# ATSAMG55G19 device description
Architecture: CORTEX-M4; Family: SAMG; Series: SAMG55
Registers are 32-bit, read-write, no defined reset value unless marked. A register's access mark holds for its fields unless they carry their own. Offsets are from the block's base; [hi:lo] are bit positions.

## PDMIC — Pulse Density Modulation Interface Controller
Instances: PDMIC0 0x4002C000, PDMIC1 0x40030000
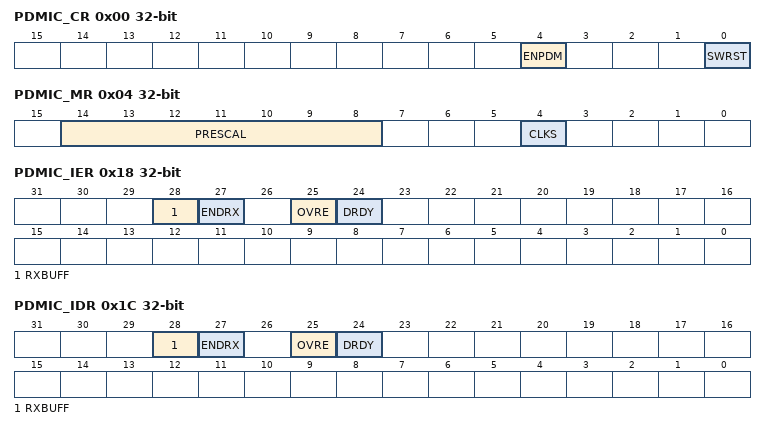
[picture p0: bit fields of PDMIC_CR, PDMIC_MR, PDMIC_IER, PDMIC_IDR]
0x00 PDMIC_CR — Control Register
  [4] ENPDM — Enable PDM
  [0] SWRST — Software Reset
0x04 PDMIC_MR — Mode Register
  [14:8] PRESCAL — Prescaler Rate Selection
  [4] CLKS — Clock Source Selection
0x14 PDMIC_CDR ro — Converted Data Register
  [31:0] DATA — Data Converted
0x18 PDMIC_IER wo (atomic set of PDMIC_IMR) — Interrupt Enable Register
  [28] RXBUFF — Receive Buffer Full Interrupt Enable
  [27] ENDRX — End of Receive Buffer Interrupt Enable
  [25] OVRE — Overrun Error Interrupt Enable
  [24] DRDY — Data Ready Interrupt Enable
0x1C PDMIC_IDR wo (atomic clear of PDMIC_IMR) — Interrupt Disable Register
  [28] RXBUFF — Receive Buffer Full Interrupt Disable
  [27] ENDRX — End of Receive Buffer Interrupt Disable
  [25] OVRE — General Overrun Error Interrupt Disable
  [24] DRDY — Data Ready Interrupt Disable
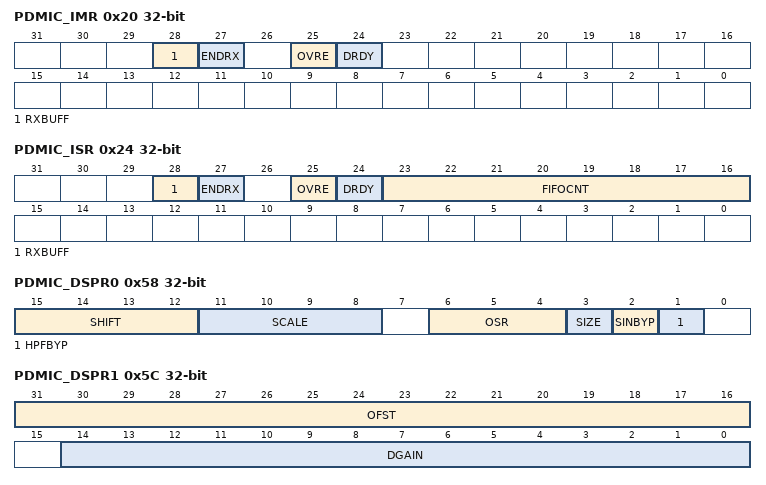
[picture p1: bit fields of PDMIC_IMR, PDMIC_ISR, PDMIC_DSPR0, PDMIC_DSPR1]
0x20 PDMIC_IMR ro (atomic read) — Interrupt Mask Register
  [28] RXBUFF — Receive Buffer Full Interrupt Mask
  [27] ENDRX — End of Receive Buffer Interrupt Mask
  [25] OVRE — General Overrun Error Interrupt Mask
  [24] DRDY — Data Ready Interrupt Mask
0x24 PDMIC_ISR ro (atomic read) — Interrupt Status Register
  [28] RXBUFF — RX Buffer Full
  [27] ENDRX — End of RX Buffer
  [25] OVRE — Overrun Error
  [24] DRDY — Data Ready
  [23:16] FIFOCNT — FIFO Count
0x58 PDMIC_DSPR0 — DSP Configuration Register 0
  [15:12] SHIFT — Data Shift
  [11:8] SCALE — Data Scale
  [6:4] OSR — Oversampling Ratio
    0=Oversampling ratio is 128; 1=Oversampling ratio is 64
  [3] SIZE — Data Size
  [2] SINBYP — SINCC Filter Bypass
  [1] HPFBYP — High-Pass Filter Bypass
0x5C PDMIC_DSPR1 — DSP Configuration Register 1
  [31:16] OFST — Offset Correction
  [14:0] DGAIN — Gain Correction
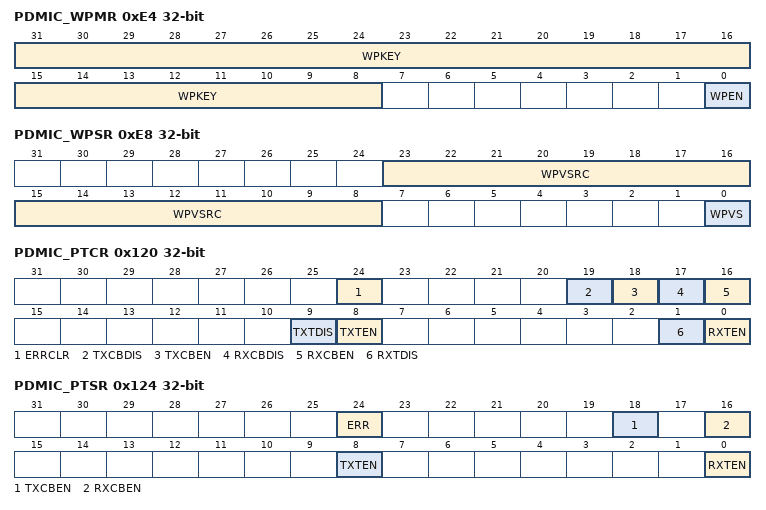
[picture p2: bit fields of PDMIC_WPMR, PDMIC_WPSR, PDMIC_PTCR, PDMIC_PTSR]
0xE4 PDMIC_WPMR — Write Protection Mode Register
  [31:8] WPKEY — Write Protect Key
    0x414443=PASSWD (Writing any other value in this field aborts the write operation of the WPEN bit.Always reads as 0.)
  [0] WPEN — Write Protection Enable
0xE8 PDMIC_WPSR ro — Write Protection Status Register
  [23:8] WPVSRC — Write Protection Violation Source
  [0] WPVS — Write Protection Violation Status
0x100 PDMIC_RPR — Receive Pointer Register
  [31:0] RXPTR
0x104 PDMIC_RCR — Receive Counter Register
  [15:0] RXCTR
0x110 PDMIC_RNPR — Receive Next Pointer Register
  [31:0] RXNPTR — Receive Next Pointer
0x114 PDMIC_RNCR — Receive Next Counter Register
  [15:0] RXNCTR — Receive Next Counter
0x120 PDMIC_PTCR wo — Transfer Control Register
  [24] ERRCLR — Transfer Bus Error Clear
  [19] TXCBDIS — Transmitter Circular Buffer Disable
  [18] TXCBEN — Transmitter Circular Buffer Enable
  [17] RXCBDIS — Receiver Circular Buffer Disable
  [16] RXCBEN — Receiver Circular Buffer Enable
  [9] TXTDIS — Transmitter Transfer Disable
  [8] TXTEN — Transmitter Transfer Enable
  [1] RXTDIS — Receiver Transfer Disable
  [0] RXTEN — Receiver Transfer Enable
0x124 PDMIC_PTSR ro — Transfer Status Register
  [24] ERR — Transfer Bus Error
  [18] TXCBEN — Transmitter Circular Buffer Enable
  [16] RXCBEN — Receiver Circular Buffer Enable
  [8] TXTEN — Transmitter Transfer Enable
  [0] RXTEN — Receiver Transfer Enable

## RSTC — Reset Controller
Instances: RSTC 0x400E1400
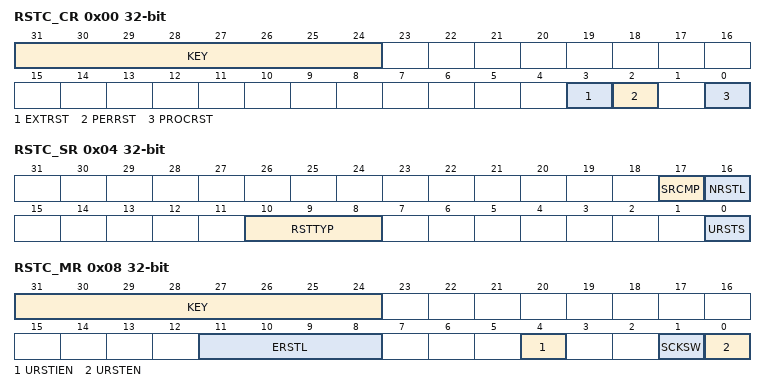
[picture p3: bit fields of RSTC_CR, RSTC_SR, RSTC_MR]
0x00 RSTC_CR wo — Control Register
  [31:24] KEY — System Reset Key
    165=PASSWD (Writing any other value in this field aborts the write operation.)
  [3] EXTRST — External Reset
  [2] PERRST — Peripheral Reset
  [0] PROCRST — Processor Reset
0x04 RSTC_SR ro — Status Register
  [17] SRCMP — Software Reset Command in Progress
  [16] NRSTL — NRST Pin Level
  [10:8] RSTTYP — Reset Type
    0=GENERAL_RST (First power-up reset); 1=BACKUP_RST (Return from Backup Mode); 2=WDT_RST (Watchdog fault occurred); 3=SOFT_RST (Processor reset required by the software); 4=USER_RST (NRST pin detected low); 7=SLCK_XTAL_RST (Slow Crystal Failure Detection fault occured)
  [0] URSTS — User Reset Status
0x08 RSTC_MR — Mode Register
  [31:24] KEY — Write Access Password
    165=PASSWD (Writing any other value in this field aborts the write operation.Always reads as 0.)
  [11:8] ERSTL — External Reset Length
  [4] URSTIEN — User Reset Interrupt Enable
  [1] SCKSW — Slow Clock Switching
  [0] URSTEN — User Reset Enable
